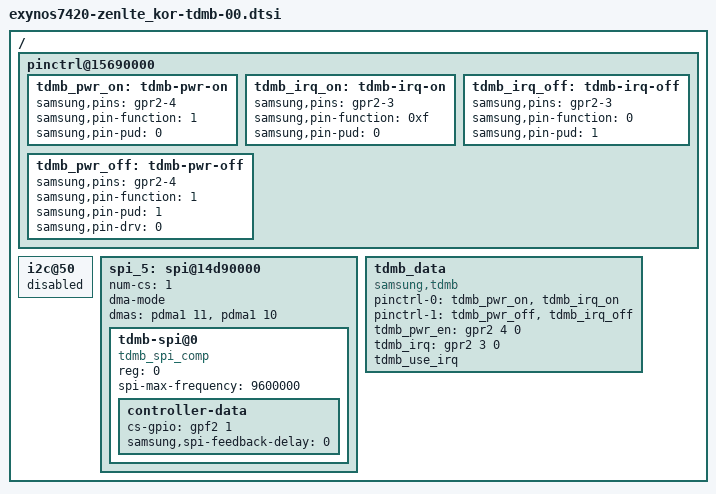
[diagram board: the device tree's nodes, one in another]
 /* Copyright (c) 2012-2014, The Linux Foundation. All rights reserved.
 *
 * This program is free software; you can redistribute it and/or modify
 * it under the terms of the GNU General Public License version 2 and
 * only version 2 as published by the Free Software Foundation.
 *
 * This program is distributed in the hope that it will be useful,
 * but WITHOUT ANY WARRANTY; without even the implied warranty of
 * MERCHANTABILITY or FITNESS FOR A PARTICULAR PURPOSE.  See the
 * GNU General Public License for more details.
 */

/{
	pinctrl@15690000 {
		tdmb_pwr_on: tdmb-pwr-on {
			samsung,pins = "gpr2-4";
			samsung,pin-function = <1>; /* OUTPUT */
			samsung,pin-pud = <0>;	/* PULL NONE */
		};
		tdmb_irq_on: tdmb-irq-on {
			samsung,pins = "gpr2-3";
			samsung,pin-function = <0xf>; /* EXT_INT31[3] */
			samsung,pin-pud = <0>;	/* PULL NONE */
		};
		tdmb_irq_off: tdmb-irq-off {
			samsung,pins = "gpr2-3";
			samsung,pin-function = <0>; /* INPUT */
			samsung,pin-pud = <1>;	/* PULL DOWN */
		};
		tdmb_pwr_off: tdmb-pwr-off {
			samsung,pins = "gpr2-4";
			samsung,pin-function = <1>; /* OUTPUT */
			samsung,pin-pud = <1>;	/* PULL DOWN */
			samsung,pin-drv = <0>;
		};
	};

	i2c@50 { /* gpr2-3 gpr2-4 */
		status = "disabled";
	};

	spi_5: spi@14d90000 {
		#address-cells = <1>;
		#size-cells = <0>;
		num-cs = <1>;

		dma-mode;
		dmas = <&pdma1 11
			&pdma1 10>;
		dma-names = "tx", "rx";

		status = "ok";

		tdmb-spi@0 {
			compatible = "tdmb_spi_comp";
			reg = <0>;
			spi-max-frequency = <9600000>;
			controller-data {
				cs-gpio = <&gpf2 1 0>;
				samsung,spi-feedback-delay = <0>;
			};
		};
	};

	tdmb_data {
		compatible = "samsung,tdmb";
		pinctrl-names = "tdmb_on", "tdmb_off";
		pinctrl-0 = <&tdmb_pwr_on &tdmb_irq_on>;
		pinctrl-1 = <&tdmb_pwr_off &tdmb_irq_off>;
		tdmb_pwr_en = <&gpr2 4 0>;
		tdmb_irq = <&gpr2 3 0>;
		tdmb_use_irq;
	};

};
